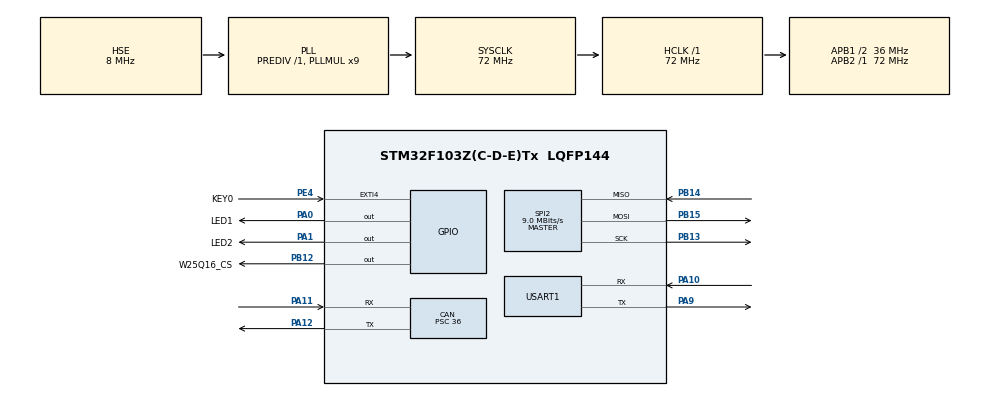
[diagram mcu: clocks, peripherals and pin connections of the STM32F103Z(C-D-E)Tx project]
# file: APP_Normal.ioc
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CAN.ABOM=ENABLE
CAN.AWUM=ENABLE
CAN.BS1=CAN_BS1_3TQ
CAN.BS2=CAN_BS2_6TQ
CAN.CalculateBaudRate=100000
CAN.CalculateTimeBit=10000
CAN.CalculateTimeQuantum=1000.0
CAN.Prescaler=36
CAN.SJW=CAN_SJW_2TQ
Mcu.Family=STM32F1
Mcu.Name=STM32F103Z(C-D-E)Tx
Mcu.Package=LQFP144
NVIC.EXTI4_IRQn=true\:3\:0\:true\:false\:true\:true\:true\:true
NVIC.PriorityGroup=NVIC_PRIORITYGROUP_4
OSC_IN.Mode=HSE-External-Oscillator
OSC_IN.Signal=RCC_OSC_IN
OSC_OUT.Mode=HSE-External-Oscillator
OSC_OUT.Signal=RCC_OSC_OUT
PA0-WKUP.GPIO_Label=LED1
PA0-WKUP.GPIO_Speed=GPIO_SPEED_FREQ_HIGH
PA0-WKUP.PinState=GPIO_PIN_SET
PA0-WKUP.Signal=GPIO_Output
PA1.GPIO_Label=LED2
PA1.GPIO_Speed=GPIO_SPEED_FREQ_HIGH
PA1.PinState=GPIO_PIN_SET
PA1.Signal=GPIO_Output
PA10.Mode=Asynchronous
PA10.Signal=USART1_RX
PA11.Mode=CAN_Activate
PA11.Signal=CAN_RX
PA12.Mode=CAN_Activate
PA12.Signal=CAN_TX
PA13.Mode=Serial_Wire
PA13.Signal=SYS_JTMS-SWDIO
PA14.Mode=Serial_Wire
PA14.Signal=SYS_JTCK-SWCLK
PA9.Mode=Asynchronous
PA9.Signal=USART1_TX
PB12.GPIO_Label=W25Q16_CS
PB12.GPIO_Speed=GPIO_SPEED_FREQ_HIGH
PB12.PinState=GPIO_PIN_SET
PB12.Signal=GPIO_Output
PB13.Mode=Full_Duplex_Master
PB13.Signal=SPI2_SCK
PB14.Mode=Full_Duplex_Master
PB14.Signal=SPI2_MISO
PB15.Mode=Full_Duplex_Master
PB15.Signal=SPI2_MOSI
PC14-OSC32_IN.Mode=LSE-External-Oscillator
PC14-OSC32_IN.Signal=RCC_OSC32_IN
PC15-OSC32_OUT.Mode=LSE-External-Oscillator
PC15-OSC32_OUT.Signal=RCC_OSC32_OUT
PE4.GPIO_Label=KEY0
PE4.GPIO_ModeDefaultEXTI=GPIO_MODE_IT_FALLING
PE4.GPIO_PuPd=GPIO_PULLUP
PE4.Signal=GPXTI4
ProjectManager.HeapSize=0x200
ProjectManager.StackSize=0x400
ProjectManager.TargetToolchain=MDK-ARM V5.32
RCC.AHBFreq_Value=72000000
RCC.APB1CLKDivider=RCC_HCLK_DIV2
RCC.APB1Freq_Value=36000000
RCC.APB1TimFreq_Value=72000000
RCC.APB2Freq_Value=72000000
RCC.APB2TimFreq_Value=72000000
RCC.HCLKFreq_Value=72000000
RCC.PLLMUL=RCC_PLL_MUL9
RCC.PLLSourceVirtual=RCC_PLLSOURCE_HSE
RCC.SYSCLKFreq_VALUE=72000000
RCC.SYSCLKSource=RCC_SYSCLKSOURCE_PLLCLK
RCC.USBFreq_Value=72000000
SPI2.BaudRatePrescaler=SPI_BAUDRATEPRESCALER_4
SPI2.CalculateBaudRate=9.0 MBits/s
SPI2.Direction=SPI_DIRECTION_2LINES
SPI2.Mode=SPI_MODE_MASTER
SPI2.VirtualType=VM_MASTER
USART1.VirtualMode=VM_ASYNC
VP_CRC_VS_CRC.Mode=CRC_Activate
board=custom

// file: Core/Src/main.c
/* USER CODE BEGIN Header */
/**
  ******************************************************************************
  * @file           : main.c
  * @brief          : Main program body
  ******************************************************************************
  * @attention
  *
  * Copyright (c) 2026 STMicroelectronics.
  * All rights reserved.
  *
  * This software is licensed under terms that can be found in the LICENSE file
  * in the root directory of this software component.
  * If no LICENSE file comes with this software, it is provided AS-IS.
  *
  ******************************************************************************
  */
/* USER CODE END Header */
#include "main.h"
#include "can.h"
#include "crc.h"
#include "spi.h"
#include "usart.h"
#include "gpio.h"

/* USER CODE BEGIN Includes */
#include "Com_Debug.h"
#include "App_Update.h"
/* USER CODE END Includes */

void SystemClock_Config(void);

int main(void)
{
  /* USER CODE BEGIN 1 */

  // 重定向中断向量表
  SCB->VTOR = APP_START_ADDR_FLASH;

  // 开启中断
  __enable_irq();
  /* USER CODE END 1 */

  /* MCU Configuration--------------------------------------------------------*/

  /* Reset of all peripherals, Initializes the Flash interface and the Systick. */
  HAL_Init();

  /* Configure the system clock */
  SystemClock_Config();

  /* Initialize all configured peripherals */
  MX_GPIO_Init();
  MX_CAN_Init();
  MX_CRC_Init();
  MX_USART1_UART_Init();
  MX_SPI2_Init();
  /* USER CODE BEGIN 2 */

  /* 配置CAN总线滤波器 */
  CAN_FilterConfig();

  /* 启动CAN总线 */
  HAL_CAN_Start(&hcan);

  /* USER CODE END 2 */

  /* Infinite loop */
  /* USER CODE BEGIN WHILE */
  while (1)
  {
    App_Update_Work();
    /* USER CODE END WHILE */

  }
}

void SystemClock_Config(void)
{
  RCC_OscInitTypeDef RCC_OscInitStruct = {0};
  RCC_ClkInitTypeDef RCC_ClkInitStruct = {0};

  /** Initializes the RCC Oscillators according to the specified parameters
  * in the RCC_OscInitTypeDef structure.
  */
  RCC_OscInitStruct.OscillatorType = RCC_OSCILLATORTYPE_HSE;
  RCC_OscInitStruct.HSEState = RCC_HSE_ON;
  RCC_OscInitStruct.HSEPredivValue = RCC_HSE_PREDIV_DIV1;
  RCC_OscInitStruct.HSIState = RCC_HSI_ON;
  RCC_OscInitStruct.PLL.PLLState = RCC_PLL_ON;
  RCC_OscInitStruct.PLL.PLLSource = RCC_PLLSOURCE_HSE;
  RCC_OscInitStruct.PLL.PLLMUL = RCC_PLL_MUL9;
  if (HAL_RCC_OscConfig(&RCC_OscInitStruct) != HAL_OK)
  {
    Error_Handler();
  }

  /** Initializes the CPU, AHB and APB buses clocks
  */
  RCC_ClkInitStruct.ClockType = RCC_CLOCKTYPE_HCLK|RCC_CLOCKTYPE_SYSCLK
                              |RCC_CLOCKTYPE_PCLK1|RCC_CLOCKTYPE_PCLK2;
  RCC_ClkInitStruct.SYSCLKSource = RCC_SYSCLKSOURCE_PLLCLK;
  RCC_ClkInitStruct.AHBCLKDivider = RCC_SYSCLK_DIV1;
  RCC_ClkInitStruct.APB1CLKDivider = RCC_HCLK_DIV2;
  RCC_ClkInitStruct.APB2CLKDivider = RCC_HCLK_DIV1;

  if (HAL_RCC_ClockConfig(&RCC_ClkInitStruct, FLASH_LATENCY_2) != HAL_OK)
  {
    Error_Handler();
  }
}

void Error_Handler(void)
{
  __disable_irq();
  while (1)
  {
  }
}
